VERSION ""

NS_ :

BS_:

BU_: VCU MCU BMS TEST_RIG

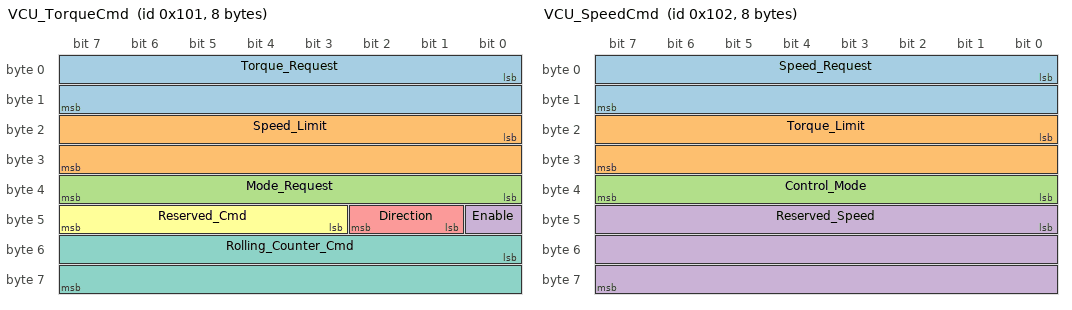
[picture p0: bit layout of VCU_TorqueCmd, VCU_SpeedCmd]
BO_ 257 VCU_TorqueCmd: 8 VCU
 SG_ Torque_Request : 0|16@1- (0.1,-3276.8) [-3276.8|3276.7] "Nm" MCU
 SG_ Speed_Limit : 16|16@1+ (1,0) [0|65535] "rpm" MCU
 SG_ Mode_Request : 32|8@1+ (1,0) [0|255] "" MCU
 SG_ Enable : 40|1@1+ (1,0) [0|1] "" MCU
 SG_ Direction : 41|2@1+ (1,0) [0|3] "" MCU
 SG_ Reserved_Cmd : 43|5@1+ (1,0) [0|31] "" MCU
 SG_ Rolling_Counter_Cmd : 48|16@1+ (1,0) [0|65535] "" MCU

BO_ 258 VCU_SpeedCmd: 8 VCU
 SG_ Speed_Request : 0|16@1+ (1,0) [0|15000] "rpm" MCU
 SG_ Torque_Limit : 16|16@1+ (0.1,0) [0|3276.7] "Nm" MCU
 SG_ Control_Mode : 32|8@1+ (1,0) [0|255] "" MCU
 SG_ Reserved_Speed : 40|24@1+ (1,0) [0|16777215] "" MCU

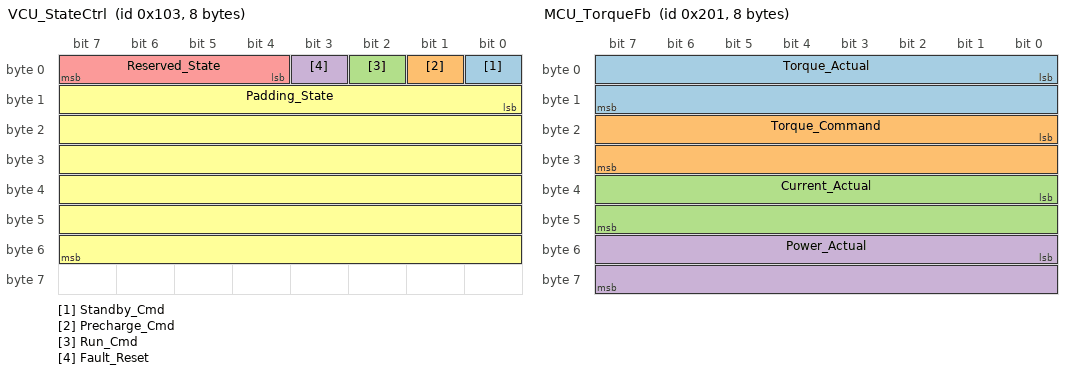
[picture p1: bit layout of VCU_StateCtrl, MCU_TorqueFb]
BO_ 259 VCU_StateCtrl: 8 VCU
 SG_ Standby_Cmd : 0|1@1+ (1,0) [0|1] "" MCU
 SG_ Precharge_Cmd : 1|1@1+ (1,0) [0|1] "" MCU
 SG_ Run_Cmd : 2|1@1+ (1,0) [0|1] "" MCU
 SG_ Fault_Reset : 3|1@1+ (1,0) [0|1] "" MCU
 SG_ Reserved_State : 4|4@1+ (1,0) [0|15] "" MCU
 SG_ Padding_State : 8|48@1+ (1,0) [0|281474976710655] "" MCU

BO_ 513 MCU_TorqueFb: 8 MCU
 SG_ Torque_Actual : 0|16@1- (0.1,-3276.8) [-3276.8|3276.7] "Nm" VCU
 SG_ Torque_Command : 16|16@1- (0.1,-3276.8) [-3276.8|3276.7] "Nm" VCU
 SG_ Current_Actual : 32|16@1- (0.1,-3276.8) [-3276.8|3276.7] "A" VCU
 SG_ Power_Actual : 48|16@1+ (0.01,0) [0|655.35] "kW" VCU

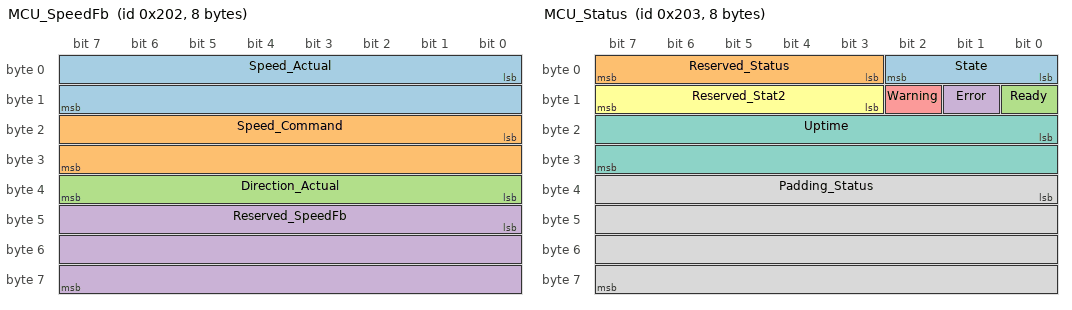
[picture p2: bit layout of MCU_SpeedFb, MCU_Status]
BO_ 514 MCU_SpeedFb: 8 MCU
 SG_ Speed_Actual : 0|16@1+ (1,0) [0|15000] "rpm" VCU
 SG_ Speed_Command : 16|16@1+ (1,0) [0|15000] "rpm" VCU
 SG_ Direction_Actual : 32|8@1+ (1,0) [0|255] "" VCU
 SG_ Reserved_SpeedFb : 40|24@1+ (1,0) [0|16777215] "" VCU

BO_ 515 MCU_Status: 8 MCU
 SG_ State : 0|3@1+ (1,0) [0|7] "" VCU
 SG_ Reserved_Status : 3|5@1+ (1,0) [0|31] "" VCU
 SG_ Ready : 8|1@1+ (1,0) [0|1] "" VCU
 SG_ Error : 9|1@1+ (1,0) [0|1] "" VCU
 SG_ Warning : 10|1@1+ (1,0) [0|1] "" VCU
 SG_ Reserved_Stat2 : 11|5@1+ (1,0) [0|31] "" VCU
 SG_ Uptime : 16|16@1+ (1,0) [0|65535] "s" VCU
 SG_ Padding_Status : 32|32@1+ (1,0) [0|4294967295] "" VCU

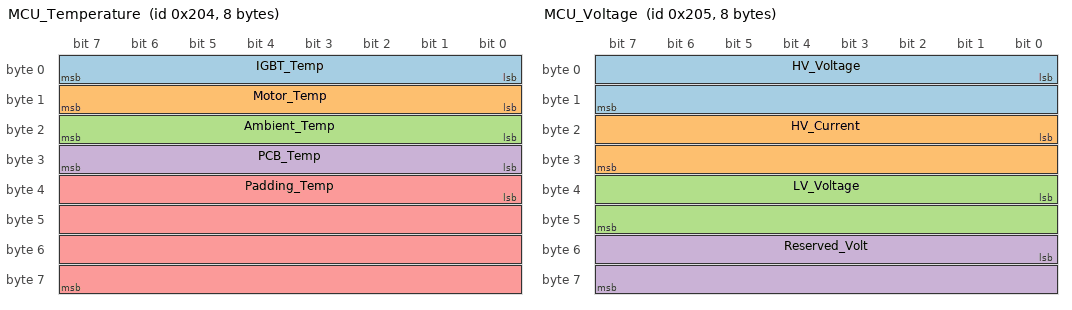
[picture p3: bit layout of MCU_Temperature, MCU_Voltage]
BO_ 516 MCU_Temperature: 8 MCU
 SG_ IGBT_Temp : 0|8@1+ (1,-40) [-40|215] "C" VCU
 SG_ Motor_Temp : 8|8@1+ (1,-40) [-40|215] "C" VCU
 SG_ Ambient_Temp : 16|8@1+ (1,-40) [-40|215] "C" VCU
 SG_ PCB_Temp : 24|8@1+ (1,-40) [-40|215] "C" VCU
 SG_ Padding_Temp : 32|32@1+ (1,0) [0|4294967295] "" VCU

BO_ 517 MCU_Voltage: 8 MCU
 SG_ HV_Voltage : 0|16@1+ (0.1,0) [0|6553.5] "V" VCU
 SG_ HV_Current : 16|16@1- (0.1,-3276.8) [-3276.8|3276.7] "A" VCU
 SG_ LV_Voltage : 32|16@1+ (0.01,0) [0|65.535] "V" VCU
 SG_ Reserved_Volt : 48|16@1+ (1,0) [0|65535] "" VCU

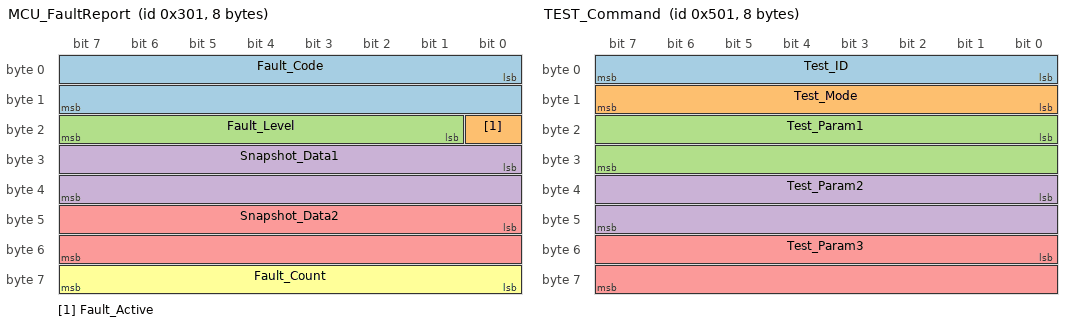
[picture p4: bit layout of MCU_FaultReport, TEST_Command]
BO_ 769 MCU_FaultReport: 8 MCU
 SG_ Fault_Code : 0|16@1+ (1,0) [0|65535] "" VCU
 SG_ Fault_Active : 16|1@1+ (1,0) [0|1] "" VCU
 SG_ Fault_Level : 17|7@1+ (1,0) [0|127] "" VCU
 SG_ Snapshot_Data1 : 24|16@1+ (1,0) [0|65535] "" VCU
 SG_ Snapshot_Data2 : 40|16@1+ (1,0) [0|65535] "" VCU
 SG_ Fault_Count : 56|8@1+ (1,0) [0|255] "" VCU

BO_ 1281 TEST_Command: 8 TEST_RIG
 SG_ Test_ID : 0|8@1+ (1,0) [0|255] "" MCU
 SG_ Test_Mode : 8|8@1+ (1,0) [0|255] "" MCU
 SG_ Test_Param1 : 16|16@1+ (1,0) [0|65535] "" MCU
 SG_ Test_Param2 : 32|16@1+ (1,0) [0|65535] "" MCU
 SG_ Test_Param3 : 48|16@1+ (1,0) [0|65535] "" MCU

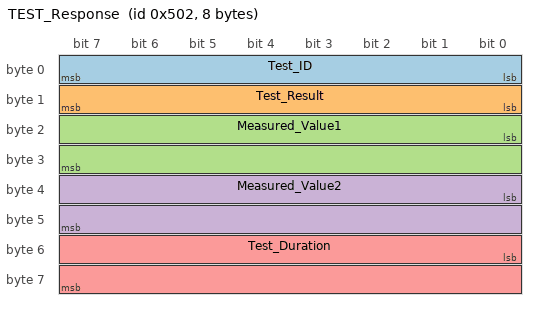
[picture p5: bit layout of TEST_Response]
BO_ 1282 TEST_Response: 8 MCU
 SG_ Test_ID : 0|8@1+ (1,0) [0|255] "" TEST_RIG
 SG_ Test_Result : 8|8@1+ (1,0) [0|255] "" TEST_RIG
 SG_ Measured_Value1 : 16|16@1- (1,-32768) [-32768|32767] "" TEST_RIG
 SG_ Measured_Value2 : 32|16@1- (1,-32768) [-32768|32767] "" TEST_RIG
 SG_ Test_Duration : 48|16@1+ (1,0) [0|65535] "ms" TEST_RIG

CM_ BU_ VCU "Vehicle Control Unit";
CM_ BU_ MCU "Motor Control Unit";
CM_ BU_ BMS "Battery Management System";
CM_ BU_ TEST_RIG "Automated Test System";

CM_ BO_ 257 "Torque command from VCU to MCU";
CM_ BO_ 258 "Speed command from VCU to MCU";
CM_ BO_ 513 "Torque feedback from MCU to VCU";
CM_ BO_ 514 "Speed feedback from MCU to VCU";
CM_ BO_ 1281 "Test command from test rig to MCU";
CM_ BO_ 1282 "Test response from MCU to test rig";

BA_DEF_ BO_ "GenMsgCycleTime" INT 0 65535;

BA_DEF_DEF_ "GenMsgCycleTime" 0;

BA_ "GenMsgCycleTime" BO_ 257 10;
BA_ "GenMsgCycleTime" BO_ 258 10;
BA_ "GenMsgCycleTime" BO_ 259 100;
BA_ "GenMsgCycleTime" BO_ 513 10;
BA_ "GenMsgCycleTime" BO_ 514 10;
BA_ "GenMsgCycleTime" BO_ 515 100;
BA_ "GenMsgCycleTime" BO_ 516 100;
BA_ "GenMsgCycleTime" BO_ 517 100;
BA_ "GenMsgCycleTime" BO_ 769 50;
